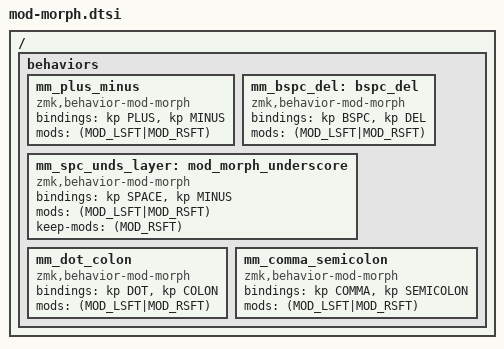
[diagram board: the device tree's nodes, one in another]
/ {
    behaviors {
        /*
         * Shifted plus types minus (-)
         *
         * Usage: &mm_plus_minus
         * Tap: +
         * Shift-Tap: -
         */
        mm_plus_minus: mm_plus_minus {
            compatible = "zmk,behavior-mod-morph";
            #binding-cells = <0>;
            bindings = <&kp PLUS>, <&kp MINUS>;
            mods = <(MOD_LSFT|MOD_RSFT)>;
        };
        /*
         * Shifted Backspace deletes
         *
         * Usage: &mm_bspc_del
         * Tap: Backspace
         * Shift-Tap: Delete
         */
        mm_bspc_del: bspc_del {
            compatible = "zmk,behavior-mod-morph";
            #binding-cells = <0>;
            bindings = <&kp BSPC>, <&kp DEL>;
            mods = <(MOD_LSFT|MOD_RSFT)>;
        };

        /*
         * Space, dash, underscore 
         *
         * Usage: &mm_spc_unds_layer
         * Tap: Space
         * LShift-Tap: _
         * RShift-Tap: -

         */
        mm_spc_unds_layer: mod_morph_underscore {
            compatible = "zmk,behavior-mod-morph";
            #binding-cells = <0>;
            bindings = <&kp SPACE>, <&kp MINUS>;
            mods = <(MOD_LSFT|MOD_RSFT)>;
            keep-mods = <(MOD_RSFT)>;
        };

        /*
         * . : '
         *
         * Usage: &mm_dot_colon_quote
         * Tap: .
         * RShift-Tap: :
        * LShift-Tap: '
         */
        mm_dot_colon: mm_dot_colon {
            compatible = "zmk,behavior-mod-morph";
            #binding-cells = <0>;
            bindings = <&kp DOT>, <&kp COLON>;
            mods = <(MOD_LSFT|MOD_RSFT)>;
        };

   /*
         * Shifted comma types semicolon
         *
         * Usage: &mm_comma_semicolon
         * Tap: ,
         * Shift-Tap: ;
         */
        mm_comma_semicolon: mm_comma_semicolon {
            compatible = "zmk,behavior-mod-morph";
            #binding-cells = <0>;
            bindings = <&kp COMMA>, <&kp SEMICOLON>;
            mods = <(MOD_LSFT|MOD_RSFT)>;
        };
 

    };
};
